AUTOSAR XML (schema 4-2-1)
standard types defined: boolean, float32, uint8, boolean_CompuMethod, boolean_DataConstr, float32_DataConstr, uint8_DataConstr
package /ComponentTypes
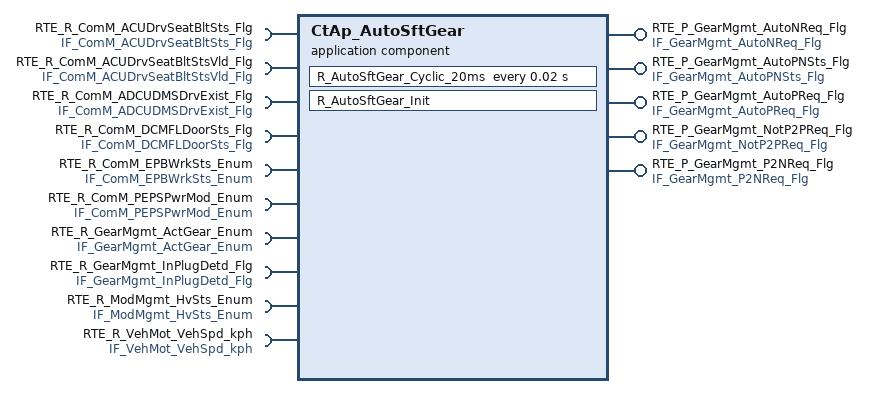
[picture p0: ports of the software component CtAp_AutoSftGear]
  application sw component type CtAp_AutoSftGear
    5 x provide port:
      RTE_P_GearMgmt_AutoNReq_Flg: nonqueued-sender-com-spec{data-element=tec_GearMgmt_AutoNReq_Flg, init-value=0}, provided-interface=IF_GearMgmt_AutoNReq_Flg
      RTE_P_GearMgmt_AutoPNSts_Flg: nonqueued-sender-com-spec{data-element=tec_GearMgmt_AutoPNSts_Flg, init-value=0}, provided-interface=IF_GearMgmt_AutoPNSts_Flg
      RTE_P_GearMgmt_AutoPReq_Flg: nonqueued-sender-com-spec{data-element=tec_GearMgmt_AutoPReq_Flg, init-value=0}, provided-interface=IF_GearMgmt_AutoPReq_Flg
      RTE_P_GearMgmt_NotP2PReq_Flg: nonqueued-sender-com-spec{data-element=tec_GearMgmt_NotP2PReq_Flg, init-value=0}, provided-interface=IF_GearMgmt_NotP2PReq_Flg
      RTE_P_GearMgmt_P2NReq_Flg: nonqueued-sender-com-spec{data-element=tec_GearMgmt_P2NReq_Flg, init-value=0}, provided-interface=IF_GearMgmt_P2NReq_Flg
    10 x require port:
      RTE_R_ComM_ACUDrvSeatBltSts_Flg: nonqueued-receiver-com-spec{data-element=tec_ComM_ACUDrvSeatBltSts_Flg, filter=data-filter-type=ALWAYS, init-value=0}, required-interface=IF_ComM_ACUDrvSeatBltSts_Flg
      RTE_R_ComM_ACUDrvSeatBltStsVld_Flg: nonqueued-receiver-com-spec{data-element=tec_ComM_ACUDrvSeatBltStsVld_Flg, filter=data-filter-type=ALWAYS, init-value=0}, required-interface=IF_ComM_ACUDrvSeatBltStsVld_Flg
      RTE_R_ComM_ADCUDMSDrvExist_Flg: nonqueued-receiver-com-spec{data-element=tec_ComM_ADCUDMSDrvrExist_Flg, filter=data-filter-type=ALWAYS, init-value=0}, required-interface=IF_ComM_ADCUDMSDrvExist_Flg
      RTE_R_ComM_DCMFLDoorSts_Flg: nonqueued-receiver-com-spec{data-element=tec_ComM_DCMFLDoorSts_Flg, filter=data-filter-type=ALWAYS, init-value=0}, required-interface=IF_ComM_DCMFLDoorSts_Flg
      RTE_R_ComM_EPBWrkSts_Enum: nonqueued-receiver-com-spec{data-element=tec_ComM_EPBWrkSts_Enum, filter=data-filter-type=ALWAYS, init-value=0}, required-interface=IF_ComM_EPBWrkSts_Enum
      RTE_R_ComM_PEPSPwrMod_Enum: nonqueued-receiver-com-spec{data-element=tec_ComM_PEPSPwrMod_Enum, filter=data-filter-type=ALWAYS, init-value=0}, required-interface=IF_ComM_PEPSPwrMod_Enum
      RTE_R_GearMgmt_ActGear_Enum: nonqueued-receiver-com-spec{data-element=tec_GearMgmt_ActGear_Enum, filter=data-filter-type=ALWAYS, init-value=0}, required-interface=IF_GearMgmt_ActGear_Enum
      RTE_R_GearMgmt_InPlugDetd_Flg: nonqueued-receiver-com-spec{data-element=tec_GearMgmt_InPlugDetd_Flg, filter=data-filter-type=ALWAYS, init-value=0}, required-interface=IF_GearMgmt_InPlugDetd_Flg
      RTE_R_ModMgmt_HvSts_Enum: nonqueued-receiver-com-spec{data-element=tec_ModMgmt_HvSts_Enum, filter=data-filter-type=ALWAYS, init-value=0}, required-interface=IF_ModMgmt_HvSts_Enum
      RTE_R_VehMot_VehSpd_kph: nonqueued-receiver-com-spec{data-element=tec_VehMot_VehSpd_kph, filter=data-filter-type=ALWAYS, init-value=0}, required-interface=IF_VehMot_VehSpd_kph
    behavior CtAp_AutoSftGear_InternalBehavior
      timing event TMT_R_AutoSftGear_Cyclic_20ms: start-on-event=R_AutoSftGear_Cyclic_20ms, period=0.02
      init event CtAp_AutoSftGear_InitEvent: start-on-event=R_AutoSftGear_Init
      runnable R_AutoSftGear_Cyclic_20ms
        data-receive-point-by-arguments:
          10 x access:
            REC_RTE_R_ComM_ACUDrvSeatBltSts_Flg_tec_ComM_ACUDrvSeatBltSts_Flg: accessed-variable=RTE_R_ComM_ACUDrvSeatBltSts_Flg.tec_ComM_ACUDrvSeatBltSts_Flg
            REC_RTE_R_ComM_ACUDrvSeatBltStsVld_Flg_tec_ComM_ACUDrvSeatBltStsVld_Flg: accessed-variable=RTE_R_ComM_ACUDrvSeatBltStsVld_Flg.tec_ComM_ACUDrvSeatBltStsVld_Flg
            REC_RTE_R_ComM_ADCUDMSDrvExist_Flg_tec_ComM_ADCUDMSDrvrExist_Flg: accessed-variable=RTE_R_ComM_ADCUDMSDrvExist_Flg.tec_ComM_ADCUDMSDrvrExist_Flg
            REC_RTE_R_ComM_DCMFLDoorSts_Flg_tec_ComM_DCMFLDoorSts_Flg: accessed-variable=RTE_R_ComM_DCMFLDoorSts_Flg.tec_ComM_DCMFLDoorSts_Flg
            REC_RTE_R_ComM_EPBWrkSts_Enum_tec_ComM_EPBWrkSts_Enum: accessed-variable=RTE_R_ComM_EPBWrkSts_Enum.tec_ComM_EPBWrkSts_Enum
            REC_RTE_R_ComM_PEPSPwrMod_Enum_tec_ComM_PEPSPwrMod_Enum: accessed-variable=RTE_R_ComM_PEPSPwrMod_Enum.tec_ComM_PEPSPwrMod_Enum
            REC_RTE_R_GearMgmt_ActGear_Enum_tec_GearMgmt_ActGear_Enum: accessed-variable=RTE_R_GearMgmt_ActGear_Enum.tec_GearMgmt_ActGear_Enum
            REC_RTE_R_GearMgmt_InPlugDetd_Flg_tec_GearMgmt_InPlugDetd_Flg: accessed-variable=RTE_R_GearMgmt_InPlugDetd_Flg.tec_GearMgmt_InPlugDetd_Flg
            REC_RTE_R_ModMgmt_HvSts_Enum_tec_ModMgmt_HvSts_Enum: accessed-variable=RTE_R_ModMgmt_HvSts_Enum.tec_ModMgmt_HvSts_Enum
            REC_RTE_R_VehMot_VehSpd_kph_tec_VehMot_VehSpd_kph: accessed-variable=RTE_R_VehMot_VehSpd_kph.tec_VehMot_VehSpd_kph
        data-send-points:
          5 x access:
            SEND_RTE_P_GearMgmt_AutoNReq_Flg_tec_GearMgmt_AutoNReq_Flg: accessed-variable=RTE_P_GearMgmt_AutoNReq_Flg.tec_GearMgmt_AutoNReq_Flg
            SEND_RTE_P_GearMgmt_AutoPNSts_Flg_tec_GearMgmt_AutoPNSts_Flg: accessed-variable=RTE_P_GearMgmt_AutoPNSts_Flg.tec_GearMgmt_AutoPNSts_Flg
            SEND_RTE_P_GearMgmt_AutoPReq_Flg_tec_GearMgmt_AutoPReq_Flg: accessed-variable=RTE_P_GearMgmt_AutoPReq_Flg.tec_GearMgmt_AutoPReq_Flg
            SEND_RTE_P_GearMgmt_NotP2PReq_Flg_tec_GearMgmt_NotP2PReq_Flg: accessed-variable=RTE_P_GearMgmt_NotP2PReq_Flg.tec_GearMgmt_NotP2PReq_Flg
            SEND_RTE_P_GearMgmt_P2NReq_Flg_tec_GearMgmt_P2NReq_Flg: accessed-variable=RTE_P_GearMgmt_P2NReq_Flg.tec_GearMgmt_P2NReq_Flg
      runnable R_AutoSftGear_Init
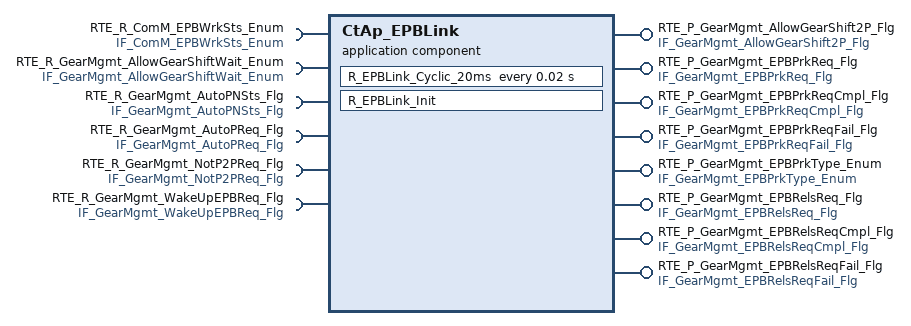
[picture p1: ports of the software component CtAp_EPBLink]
  application sw component type CtAp_EPBLink
    8 x provide port:
      RTE_P_GearMgmt_AllowGearShift2P_Flg: nonqueued-sender-com-spec{data-element=tec_GearMgmt_AllowGearShift2P_Flg, init-value=0}, provided-interface=IF_GearMgmt_AllowGearShift2P_Flg
      RTE_P_GearMgmt_EPBPrkReq_Flg: nonqueued-sender-com-spec{data-element=tec_GearMgmt_EPBPrkReq_Flg, init-value=0}, provided-interface=IF_GearMgmt_EPBPrkReq_Flg
      RTE_P_GearMgmt_EPBPrkReqCmpl_Flg: nonqueued-sender-com-spec{data-element=tec_GearMgmt_EPBPrkReqCmpl_Flg, init-value=0}, provided-interface=IF_GearMgmt_EPBPrkReqCmpl_Flg
      RTE_P_GearMgmt_EPBPrkReqFail_Flg: nonqueued-sender-com-spec{data-element=tec_GearMgmt_EPBPrkReqFail_Flg, init-value=0}, provided-interface=IF_GearMgmt_EPBPrkReqFail_Flg
      RTE_P_GearMgmt_EPBPrkType_Enum: nonqueued-sender-com-spec{data-element=tec_GearMgmt_EPBPrkType_Enum, init-value=0}, provided-interface=IF_GearMgmt_EPBPrkType_Enum
      RTE_P_GearMgmt_EPBRelsReq_Flg: nonqueued-sender-com-spec{data-element=tec_GearMgmt_EPBRelsReq_Flg, init-value=0}, provided-interface=IF_GearMgmt_EPBRelsReq_Flg
      RTE_P_GearMgmt_EPBRelsReqCmpl_Flg: nonqueued-sender-com-spec{data-element=tec_GearMgmt_EPBRelsReqCmpl_Flg, init-value=0}, provided-interface=IF_GearMgmt_EPBRelsReqCmpl_Flg
      RTE_P_GearMgmt_EPBRelsReqFail_Flg: nonqueued-sender-com-spec{data-element=tec_GearMgmt_EPBRelsReqFail_Flg, init-value=0}, provided-interface=IF_GearMgmt_EPBRelsReqFail_Flg
    6 x require port:
      RTE_R_ComM_EPBWrkSts_Enum: nonqueued-receiver-com-spec{data-element=tec_ComM_EPBWrkSts_Enum, filter=data-filter-type=ALWAYS, init-value=0}, required-interface=IF_ComM_EPBWrkSts_Enum
      RTE_R_GearMgmt_AllowGearShiftWait_Enum: nonqueued-receiver-com-spec{data-element=tec_GearMgmt_AllowGearShiftWait_Enum, filter=data-filter-type=ALWAYS, init-value=0}, required-interface=IF_GearMgmt_AllowGearShiftWait_Enum
      RTE_R_GearMgmt_AutoPNSts_Flg: nonqueued-receiver-com-spec{data-element=tec_GearMgmt_AutoPNSts_Flg, filter=data-filter-type=ALWAYS, init-value=0}, required-interface=IF_GearMgmt_AutoPNSts_Flg
      RTE_R_GearMgmt_AutoPReq_Flg: nonqueued-receiver-com-spec{data-element=tec_GearMgmt_AutoPReq_Flg, filter=data-filter-type=ALWAYS, init-value=0}, required-interface=IF_GearMgmt_AutoPReq_Flg
      RTE_R_GearMgmt_NotP2PReq_Flg: nonqueued-receiver-com-spec{data-element=tec_GearMgmt_NotP2PReq_Flg, filter=data-filter-type=ALWAYS, init-value=0}, required-interface=IF_GearMgmt_NotP2PReq_Flg
      RTE_R_GearMgmt_WakeUpEPBReq_Flg: nonqueued-receiver-com-spec{data-element=tec_GearMgmt_WakeUpEPBReq_Flg, filter=data-filter-type=ALWAYS, init-value=0}, required-interface=IF_GearMgmt_WakeUpEPBReq_Flg
    behavior CtAp_EPBLink_InternalBehavior
      timing event TMT_R_EPBLink_Cyclic_20ms: start-on-event=R_EPBLink_Cyclic_20ms, period=0.02
      init event CtAp_EPBLink_InitEvent: start-on-event=R_EPBLink_Init
      runnable R_EPBLink_Cyclic_20ms
        data-receive-point-by-arguments:
          6 x access:
            REC_RTE_R_ComM_EPBWrkSts_Enum_tec_ComM_EPBWrkSts_Enum: accessed-variable=RTE_R_ComM_EPBWrkSts_Enum.tec_ComM_EPBWrkSts_Enum
            REC_RTE_R_GearMgmt_AllowGearShiftWait_Enum_tec_GearMgmt_AllowGearShiftWait_Enum: accessed-variable=RTE_R_GearMgmt_AllowGearShiftWait_Enum.tec_GearMgmt_AllowGearShiftWait_Enum
            REC_RTE_R_GearMgmt_AutoPNSts_Flg_tec_GearMgmt_AutoPNSts_Flg: accessed-variable=RTE_R_GearMgmt_AutoPNSts_Flg.tec_GearMgmt_AutoPNSts_Flg
            REC_RTE_R_GearMgmt_AutoPReq_Flg_tec_GearMgmt_AutoPReq_Flg: accessed-variable=RTE_R_GearMgmt_AutoPReq_Flg.tec_GearMgmt_AutoPReq_Flg
            REC_RTE_R_GearMgmt_NotP2PReq_Flg_tec_GearMgmt_NotP2PReq_Flg: accessed-variable=RTE_R_GearMgmt_NotP2PReq_Flg.tec_GearMgmt_NotP2PReq_Flg
            REC_RTE_R_GearMgmt_WakeUpEPBReq_Flg_tec_GearMgmt_WakeUpEPBReq_Flg: accessed-variable=RTE_R_GearMgmt_WakeUpEPBReq_Flg.tec_GearMgmt_WakeUpEPBReq_Flg
        data-send-points:
          8 x access:
            SEND_RTE_P_GearMgmt_AllowGearShift2P_Flg_tec_GearMgmt_AllowGearShift2P_Flg: accessed-variable=RTE_P_GearMgmt_AllowGearShift2P_Flg.tec_GearMgmt_AllowGearShift2P_Flg
            SEND_RTE_P_GearMgmt_EPBPrkReq_Flg_tec_GearMgmt_EPBPrkReq_Flg: accessed-variable=RTE_P_GearMgmt_EPBPrkReq_Flg.tec_GearMgmt_EPBPrkReq_Flg
            SEND_RTE_P_GearMgmt_EPBPrkReqCmpl_Flg_tec_GearMgmt_EPBPrkReqCmpl_Flg: accessed-variable=RTE_P_GearMgmt_EPBPrkReqCmpl_Flg.tec_GearMgmt_EPBPrkReqCmpl_Flg
            SEND_RTE_P_GearMgmt_EPBPrkReqFail_Flg_tec_GearMgmt_EPBPrkReqFail_Flg: accessed-variable=RTE_P_GearMgmt_EPBPrkReqFail_Flg.tec_GearMgmt_EPBPrkReqFail_Flg
            SEND_RTE_P_GearMgmt_EPBPrkType_Enum_tec_GearMgmt_EPBPrkType_Enum: accessed-variable=RTE_P_GearMgmt_EPBPrkType_Enum.tec_GearMgmt_EPBPrkType_Enum
            SEND_RTE_P_GearMgmt_EPBRelsReq_Flg_tec_GearMgmt_EPBRelsReq_Flg: accessed-variable=RTE_P_GearMgmt_EPBRelsReq_Flg.tec_GearMgmt_EPBRelsReq_Flg
            SEND_RTE_P_GearMgmt_EPBRelsReqCmpl_Flg_tec_GearMgmt_EPBRelsReqCmpl_Flg: accessed-variable=RTE_P_GearMgmt_EPBRelsReqCmpl_Flg.tec_GearMgmt_EPBRelsReqCmpl_Flg
            SEND_RTE_P_GearMgmt_EPBRelsReqFail_Flg_tec_GearMgmt_EPBRelsReqFail_Flg: accessed-variable=RTE_P_GearMgmt_EPBRelsReqFail_Flg.tec_GearMgmt_EPBRelsReqFail_Flg
      runnable R_EPBLink_Init
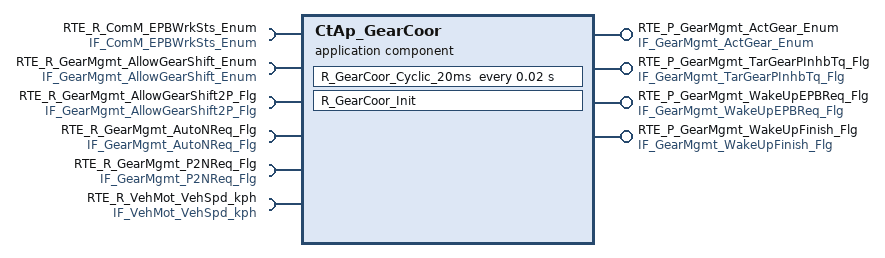
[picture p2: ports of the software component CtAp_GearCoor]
  application sw component type CtAp_GearCoor
    4 x provide port:
      RTE_P_GearMgmt_ActGear_Enum: nonqueued-sender-com-spec{data-element=tec_GearMgmt_ActGear_Enum, init-value=0}, provided-interface=IF_GearMgmt_ActGear_Enum
      RTE_P_GearMgmt_TarGearPInhbTq_Flg: nonqueued-sender-com-spec{data-element=tec_GearMgmt_TarGearPInhbTq_Flg, init-value=0}, provided-interface=IF_GearMgmt_TarGearPInhbTq_Flg
      RTE_P_GearMgmt_WakeUpEPBReq_Flg: nonqueued-sender-com-spec{data-element=tec_GearMgmt_WakeUpEPBReq_Flg, init-value=0}, provided-interface=IF_GearMgmt_WakeUpEPBReq_Flg
      RTE_P_GearMgmt_WakeUpFinish_Flg: nonqueued-sender-com-spec{data-element=tec_GearMgmt_WakeUpFinish_Flg, init-value=0}, provided-interface=IF_GearMgmt_WakeUpFinish_Flg
    6 x require port:
      RTE_R_ComM_EPBWrkSts_Enum: nonqueued-receiver-com-spec{data-element=tec_ComM_EPBWrkSts_Enum, filter=data-filter-type=ALWAYS, init-value=0}, required-interface=IF_ComM_EPBWrkSts_Enum
      RTE_R_GearMgmt_AllowGearShift_Enum: nonqueued-receiver-com-spec{data-element=tec_GearMgmt_AllowGearShift_Enum, filter=data-filter-type=ALWAYS, init-value=0}, required-interface=IF_GearMgmt_AllowGearShift_Enum
      RTE_R_GearMgmt_AllowGearShift2P_Flg: nonqueued-receiver-com-spec{data-element=tec_GearMgmt_AllowGearShift2P_Flg, filter=data-filter-type=ALWAYS, init-value=0}, required-interface=IF_GearMgmt_AllowGearShift2P_Flg
      RTE_R_GearMgmt_AutoNReq_Flg: nonqueued-receiver-com-spec{data-element=tec_GearMgmt_AutoNReq_Flg, filter=data-filter-type=ALWAYS, init-value=0}, required-interface=IF_GearMgmt_AutoNReq_Flg
      RTE_R_GearMgmt_P2NReq_Flg: nonqueued-receiver-com-spec{data-element=tec_GearMgmt_P2NReq_Flg, filter=data-filter-type=ALWAYS, init-value=0}, required-interface=IF_GearMgmt_P2NReq_Flg
      RTE_R_VehMot_VehSpd_kph: nonqueued-receiver-com-spec{data-element=tec_VehMot_VehSpd_kph, filter=data-filter-type=ALWAYS, init-value=0}, required-interface=IF_VehMot_VehSpd_kph
    behavior CtAp_GearCoor_InternalBehavior
      timing event TMT_R_GearCoor_Cyclic_20ms: start-on-event=R_GearCoor_Cyclic_20ms, period=0.02
      init event CtAp_GearCoor_InitEvent: start-on-event=R_GearCoor_Init
      runnable R_GearCoor_Cyclic_20ms
        data-receive-point-by-arguments:
          6 x access:
            REC_RTE_R_ComM_EPBWrkSts_Enum_tec_ComM_EPBWrkSts_Enum: accessed-variable=RTE_R_ComM_EPBWrkSts_Enum.tec_ComM_EPBWrkSts_Enum
            REC_RTE_R_GearMgmt_AllowGearShift_Enum_tec_GearMgmt_AllowGearShift_Enum: accessed-variable=RTE_R_GearMgmt_AllowGearShift_Enum.tec_GearMgmt_AllowGearShift_Enum
            REC_RTE_R_GearMgmt_AllowGearShift2P_Flg_tec_GearMgmt_AllowGearShift2P_Flg: accessed-variable=RTE_R_GearMgmt_AllowGearShift2P_Flg.tec_GearMgmt_AllowGearShift2P_Flg
            REC_RTE_R_GearMgmt_AutoNReq_Flg_tec_GearMgmt_AutoNReq_Flg: accessed-variable=RTE_R_GearMgmt_AutoNReq_Flg.tec_GearMgmt_AutoNReq_Flg
            REC_RTE_R_GearMgmt_P2NReq_Flg_tec_GearMgmt_P2NReq_Flg: accessed-variable=RTE_R_GearMgmt_P2NReq_Flg.tec_GearMgmt_P2NReq_Flg
            REC_RTE_R_VehMot_VehSpd_kph_tec_VehMot_VehSpd_kph: accessed-variable=RTE_R_VehMot_VehSpd_kph.tec_VehMot_VehSpd_kph
        data-send-points:
          4 x access:
            SEND_RTE_P_GearMgmt_ActGear_Enum_tec_GearMgmt_ActGear_Enum: accessed-variable=RTE_P_GearMgmt_ActGear_Enum.tec_GearMgmt_ActGear_Enum
            SEND_RTE_P_GearMgmt_TarGearPInhbTq_Flg_tec_GearMgmt_TarGearPInhbTq_Flg: accessed-variable=RTE_P_GearMgmt_TarGearPInhbTq_Flg.tec_GearMgmt_TarGearPInhbTq_Flg
            SEND_RTE_P_GearMgmt_WakeUpEPBReq_Flg_tec_GearMgmt_WakeUpEPBReq_Flg: accessed-variable=RTE_P_GearMgmt_WakeUpEPBReq_Flg.tec_GearMgmt_WakeUpEPBReq_Flg
            SEND_RTE_P_GearMgmt_WakeUpFinish_Flg_tec_GearMgmt_WakeUpFinish_Flg: accessed-variable=RTE_P_GearMgmt_WakeUpFinish_Flg.tec_GearMgmt_WakeUpFinish_Flg
      runnable R_GearCoor_Init
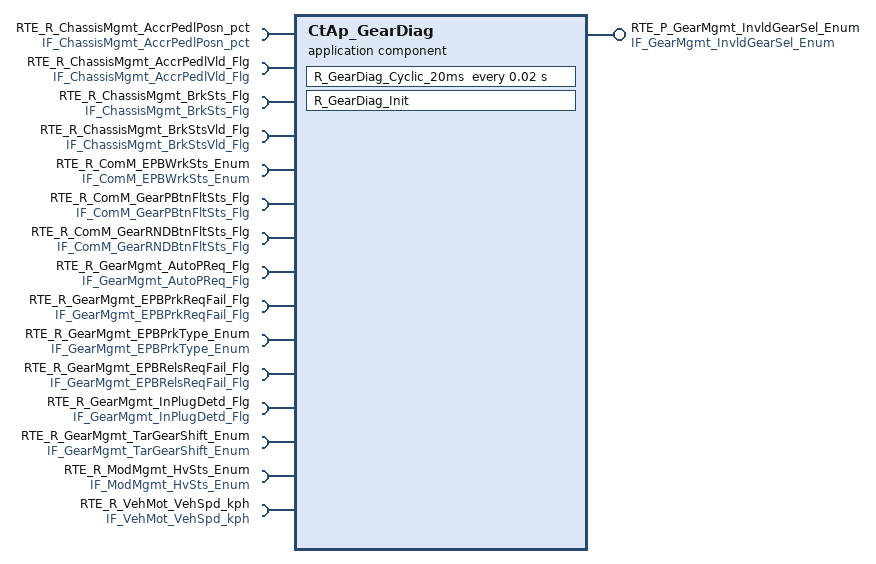
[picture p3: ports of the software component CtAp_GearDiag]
  application sw component type CtAp_GearDiag
    provide port RTE_P_GearMgmt_InvldGearSel_Enum: nonqueued-sender-com-spec{data-element=tec_GearMgmt_InvldGearSel_Enum, init-value=0}, provided-interface=IF_GearMgmt_InvldGearSel_Enum
    15 x require port:
      RTE_R_ChassisMgmt_AccrPedlPosn_pct: nonqueued-receiver-com-spec{data-element=tec_ChassisMgmt_AccrPedlPosn_pct, filter=data-filter-type=ALWAYS, init-value=0}, required-interface=IF_ChassisMgmt_AccrPedlPosn_pct
      RTE_R_ChassisMgmt_AccrPedlVld_Flg: nonqueued-receiver-com-spec{data-element=tec_ChassisMgmt_AccrPedlVld_Flg, filter=data-filter-type=ALWAYS, init-value=0}, required-interface=IF_ChassisMgmt_AccrPedlVld_Flg
      RTE_R_ChassisMgmt_BrkSts_Flg: nonqueued-receiver-com-spec{data-element=tec_ChassisMgmt_BrkSts_Flg, filter=data-filter-type=ALWAYS, init-value=0}, required-interface=IF_ChassisMgmt_BrkSts_Flg
      RTE_R_ChassisMgmt_BrkStsVld_Flg: nonqueued-receiver-com-spec{data-element=tec_ChassisMgmt_BrkStsVld_Flg, filter=data-filter-type=ALWAYS, init-value=0}, required-interface=IF_ChassisMgmt_BrkStsVld_Flg
      RTE_R_ComM_EPBWrkSts_Enum: nonqueued-receiver-com-spec{data-element=tec_ComM_EPBWrkSts_Enum, filter=data-filter-type=ALWAYS, init-value=0}, required-interface=IF_ComM_EPBWrkSts_Enum
      RTE_R_ComM_GearPBtnFltSts_Flg: nonqueued-receiver-com-spec{data-element=tec_ComM_GearPBtnFltSts_Flg, filter=data-filter-type=ALWAYS, init-value=0}, required-interface=IF_ComM_GearPBtnFltSts_Flg
      RTE_R_ComM_GearRNDBtnFltSts_Flg: nonqueued-receiver-com-spec{data-element=tec_ComM_GearRNDBtnFltSts_Flg, filter=data-filter-type=ALWAYS, init-value=0}, required-interface=IF_ComM_GearRNDBtnFltSts_Flg
      RTE_R_GearMgmt_AutoPReq_Flg: nonqueued-receiver-com-spec{data-element=tec_GearMgmt_AutoPReq_Flg, filter=data-filter-type=ALWAYS, init-value=0}, required-interface=IF_GearMgmt_AutoPReq_Flg
      RTE_R_GearMgmt_EPBPrkReqFail_Flg: nonqueued-receiver-com-spec{data-element=tec_GearMgmt_EPBPrkReqFail_Flg, filter=data-filter-type=ALWAYS, init-value=0}, required-interface=IF_GearMgmt_EPBPrkReqFail_Flg
      RTE_R_GearMgmt_EPBPrkType_Enum: nonqueued-receiver-com-spec{data-element=tec_GearMgmt_EPBPrkType_Enum, filter=data-filter-type=ALWAYS, init-value=0}, required-interface=IF_GearMgmt_EPBPrkType_Enum
      RTE_R_GearMgmt_EPBRelsReqFail_Flg: nonqueued-receiver-com-spec{data-element=tec_GearMgmt_EPBRelsReqFail_Flg, filter=data-filter-type=ALWAYS, init-value=0}, required-interface=IF_GearMgmt_EPBRelsReqFail_Flg
      RTE_R_GearMgmt_InPlugDetd_Flg: nonqueued-receiver-com-spec{data-element=tec_GearMgmt_InPlugDetd_Flg, filter=data-filter-type=ALWAYS, init-value=0}, required-interface=IF_GearMgmt_InPlugDetd_Flg
      RTE_R_GearMgmt_TarGearShift_Enum: nonqueued-receiver-com-spec{data-element=tec_GearMgmt_TarGearShift_Enum, filter=data-filter-type=ALWAYS, init-value=0}, required-interface=IF_GearMgmt_TarGearShift_Enum
      RTE_R_ModMgmt_HvSts_Enum: nonqueued-receiver-com-spec{data-element=tec_ModMgmt_HvSts_Enum, filter=data-filter-type=ALWAYS, init-value=0}, required-interface=IF_ModMgmt_HvSts_Enum
      RTE_R_VehMot_VehSpd_kph: nonqueued-receiver-com-spec{data-element=tec_VehMot_VehSpd_kph, filter=data-filter-type=ALWAYS, init-value=0}, required-interface=IF_VehMot_VehSpd_kph
    behavior CtAp_GearDiag_InternalBehavior
      timing event TMT_R_GearDiag_Cyclic_20ms: start-on-event=R_GearDiag_Cyclic_20ms, period=0.02
      init event CtAp_GearDiag_InitEvent: start-on-event=R_GearDiag_Init
      runnable R_GearDiag_Cyclic_20ms
        data-receive-point-by-arguments:
          15 x access:
            REC_RTE_R_ChassisMgmt_AccrPedlPosn_pct_tec_ChassisMgmt_AccrPedlPosn_pct: accessed-variable=RTE_R_ChassisMgmt_AccrPedlPosn_pct.tec_ChassisMgmt_AccrPedlPosn_pct
            REC_RTE_R_ChassisMgmt_AccrPedlVld_Flg_tec_ChassisMgmt_AccrPedlVld_Flg: accessed-variable=RTE_R_ChassisMgmt_AccrPedlVld_Flg.tec_ChassisMgmt_AccrPedlVld_Flg
            REC_RTE_R_ChassisMgmt_BrkSts_Flg_tec_ChassisMgmt_BrkSts_Flg: accessed-variable=RTE_R_ChassisMgmt_BrkSts_Flg.tec_ChassisMgmt_BrkSts_Flg
            REC_RTE_R_ChassisMgmt_BrkStsVld_Flg_tec_ChassisMgmt_BrkStsVld_Flg: accessed-variable=RTE_R_ChassisMgmt_BrkStsVld_Flg.tec_ChassisMgmt_BrkStsVld_Flg
            REC_RTE_R_ComM_EPBWrkSts_Enum_tec_ComM_EPBWrkSts_Enum: accessed-variable=RTE_R_ComM_EPBWrkSts_Enum.tec_ComM_EPBWrkSts_Enum
            REC_RTE_R_ComM_GearPBtnFltSts_Flg_tec_ComM_GearPBtnFltSts_Flg: accessed-variable=RTE_R_ComM_GearPBtnFltSts_Flg.tec_ComM_GearPBtnFltSts_Flg
            REC_RTE_R_ComM_GearRNDBtnFltSts_Flg_tec_ComM_GearRNDBtnFltSts_Flg: accessed-variable=RTE_R_ComM_GearRNDBtnFltSts_Flg.tec_ComM_GearRNDBtnFltSts_Flg
            REC_RTE_R_GearMgmt_AutoPReq_Flg_tec_GearMgmt_AutoPReq_Flg: accessed-variable=RTE_R_GearMgmt_AutoPReq_Flg.tec_GearMgmt_AutoPReq_Flg
            REC_RTE_R_GearMgmt_EPBPrkReqFail_Flg_tec_GearMgmt_EPBPrkReqFail_Flg: accessed-variable=RTE_R_GearMgmt_EPBPrkReqFail_Flg.tec_GearMgmt_EPBPrkReqFail_Flg
            REC_RTE_R_GearMgmt_EPBPrkType_Enum_tec_GearMgmt_EPBPrkType_Enum: accessed-variable=RTE_R_GearMgmt_EPBPrkType_Enum.tec_GearMgmt_EPBPrkType_Enum
            REC_RTE_R_GearMgmt_EPBRelsReqFail_Flg_tec_GearMgmt_EPBRelsReqFail_Flg: accessed-variable=RTE_R_GearMgmt_EPBRelsReqFail_Flg.tec_GearMgmt_EPBRelsReqFail_Flg
            REC_RTE_R_GearMgmt_InPlugDetd_Flg_tec_GearMgmt_InPlugDetd_Flg: accessed-variable=RTE_R_GearMgmt_InPlugDetd_Flg.tec_GearMgmt_InPlugDetd_Flg
            REC_RTE_R_GearMgmt_TarGearShift_Enum_tec_GearMgmt_TarGearShift_Enum: accessed-variable=RTE_R_GearMgmt_TarGearShift_Enum.tec_GearMgmt_TarGearShift_Enum
            REC_RTE_R_ModMgmt_HvSts_Enum_tec_ModMgmt_HvSts_Enum: accessed-variable=RTE_R_ModMgmt_HvSts_Enum.tec_ModMgmt_HvSts_Enum
            REC_RTE_R_VehMot_VehSpd_kph_tec_VehMot_VehSpd_kph: accessed-variable=RTE_R_VehMot_VehSpd_kph.tec_VehMot_VehSpd_kph
        data-send-points:
          access SEND_RTE_P_GearMgmt_InvldGearSel_Enum_tec_GearMgmt_InvldGearSel_Enum: accessed-variable=RTE_P_GearMgmt_InvldGearSel_Enum.tec_GearMgmt_InvldGearSel_Enum
      runnable R_GearDiag_Init
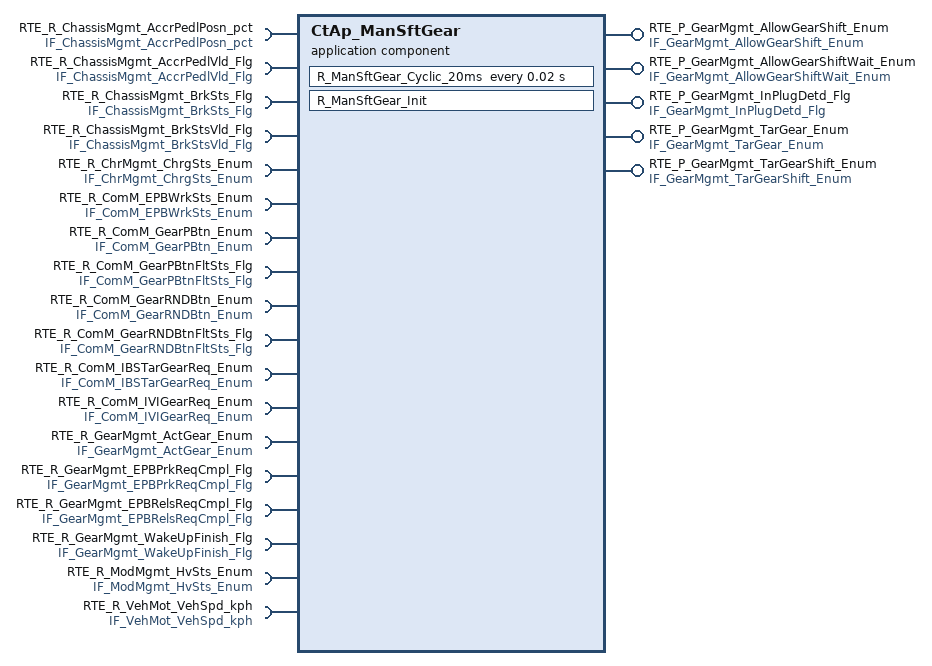
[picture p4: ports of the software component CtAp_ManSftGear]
  application sw component type CtAp_ManSftGear
    5 x provide port:
      RTE_P_GearMgmt_AllowGearShift_Enum: nonqueued-sender-com-spec{data-element=tec_GearMgmt_AllowGearShift_Enum, init-value=0}, provided-interface=IF_GearMgmt_AllowGearShift_Enum
      RTE_P_GearMgmt_AllowGearShiftWait_Enum: nonqueued-sender-com-spec{data-element=tec_GearMgmt_AllowGearShiftWait_Enum, init-value=0}, provided-interface=IF_GearMgmt_AllowGearShiftWait_Enum
      RTE_P_GearMgmt_InPlugDetd_Flg: nonqueued-sender-com-spec{data-element=tec_GearMgmt_InPlugDetd_Flg, init-value=0}, provided-interface=IF_GearMgmt_InPlugDetd_Flg
      RTE_P_GearMgmt_TarGear_Enum: nonqueued-sender-com-spec{data-element=tec_GearMgmt_TarGear_Enum, init-value=0}, provided-interface=IF_GearMgmt_TarGear_Enum
      RTE_P_GearMgmt_TarGearShift_Enum: nonqueued-sender-com-spec{data-element=tec_GearMgmt_TarGearShift_Enum, init-value=0}, provided-interface=IF_GearMgmt_TarGearShift_Enum
    18 x require port:
      RTE_R_ChassisMgmt_AccrPedlPosn_pct: nonqueued-receiver-com-spec{data-element=tec_ChassisMgmt_AccrPedlPosn_pct, filter=data-filter-type=ALWAYS, init-value=0}, required-interface=IF_ChassisMgmt_AccrPedlPosn_pct
      RTE_R_ChassisMgmt_AccrPedlVld_Flg: nonqueued-receiver-com-spec{data-element=tec_ChassisMgmt_AccrPedlVld_Flg, filter=data-filter-type=ALWAYS, init-value=0}, required-interface=IF_ChassisMgmt_AccrPedlVld_Flg
      RTE_R_ChassisMgmt_BrkSts_Flg: nonqueued-receiver-com-spec{data-element=tec_ChassisMgmt_BrkSts_Flg, filter=data-filter-type=ALWAYS, init-value=0}, required-interface=IF_ChassisMgmt_BrkSts_Flg
      RTE_R_ChassisMgmt_BrkStsVld_Flg: nonqueued-receiver-com-spec{data-element=tec_ChassisMgmt_BrkStsVld_Flg, filter=data-filter-type=ALWAYS, init-value=0}, required-interface=IF_ChassisMgmt_BrkStsVld_Flg
      RTE_R_ChrMgmt_ChrgSts_Enum: nonqueued-receiver-com-spec{data-element=tec_ChrMgmt_ChrgSts_Enum, filter=data-filter-type=ALWAYS, init-value=0}, required-interface=IF_ChrMgmt_ChrgSts_Enum
      RTE_R_ComM_EPBWrkSts_Enum: nonqueued-receiver-com-spec{data-element=tec_ComM_EPBWrkSts_Enum, filter=data-filter-type=ALWAYS, init-value=0}, required-interface=IF_ComM_EPBWrkSts_Enum
      RTE_R_ComM_GearPBtn_Enum: nonqueued-receiver-com-spec{data-element=tec_ComM_GearPBtn_Enum, filter=data-filter-type=ALWAYS, init-value=0}, required-interface=IF_ComM_GearPBtn_Enum
      RTE_R_ComM_GearPBtnFltSts_Flg: nonqueued-receiver-com-spec{data-element=tec_ComM_GearPBtnFltSts_Flg, filter=data-filter-type=ALWAYS, init-value=0}, required-interface=IF_ComM_GearPBtnFltSts_Flg
      RTE_R_ComM_GearRNDBtn_Enum: nonqueued-receiver-com-spec{data-element=tec_ComM_GearRNDBtn_Enum, filter=data-filter-type=ALWAYS, init-value=0}, required-interface=IF_ComM_GearRNDBtn_Enum
      RTE_R_ComM_GearRNDBtnFltSts_Flg: nonqueued-receiver-com-spec{data-element=tec_ComM_GearRNDBtnFltSts_Flg, filter=data-filter-type=ALWAYS, init-value=0}, required-interface=IF_ComM_GearRNDBtnFltSts_Flg
      RTE_R_ComM_IBSTarGearReq_Enum: nonqueued-receiver-com-spec{data-element=tec_ComM_IBSTarGearReq_Enum, filter=data-filter-type=ALWAYS, init-value=0}, required-interface=IF_ComM_IBSTarGearReq_Enum
      RTE_R_ComM_IVIGearReq_Enum: nonqueued-receiver-com-spec{data-element=tec_ComM_IVIGearReq_Enum, filter=data-filter-type=ALWAYS, init-value=0}, required-interface=IF_ComM_IVIGearReq_Enum
      RTE_R_GearMgmt_ActGear_Enum: nonqueued-receiver-com-spec{data-element=tec_GearMgmt_ActGear_Enum, filter=data-filter-type=ALWAYS, init-value=0}, required-interface=IF_GearMgmt_ActGear_Enum
      RTE_R_GearMgmt_EPBPrkReqCmpl_Flg: nonqueued-receiver-com-spec{data-element=tec_GearMgmt_EPBPrkReqCmpl_Flg, filter=data-filter-type=ALWAYS, init-value=0}, required-interface=IF_GearMgmt_EPBPrkReqCmpl_Flg
      RTE_R_GearMgmt_EPBRelsReqCmpl_Flg: nonqueued-receiver-com-spec{data-element=tec_GearMgmt_EPBRelsReqCmpl_Flg, filter=data-filter-type=ALWAYS, init-value=0}, required-interface=IF_GearMgmt_EPBRelsReqCmpl_Flg
      RTE_R_GearMgmt_WakeUpFinish_Flg: nonqueued-receiver-com-spec{data-element=tec_GearMgmt_WakeUpFinish_Flg, filter=data-filter-type=ALWAYS, init-value=0}, required-interface=IF_GearMgmt_WakeUpFinish_Flg
      RTE_R_ModMgmt_HvSts_Enum: nonqueued-receiver-com-spec{data-element=tec_ModMgmt_HvSts_Enum, filter=data-filter-type=ALWAYS, init-value=0}, required-interface=IF_ModMgmt_HvSts_Enum
      RTE_R_VehMot_VehSpd_kph: nonqueued-receiver-com-spec{data-element=tec_VehMot_VehSpd_kph, filter=data-filter-type=ALWAYS, init-value=0}, required-interface=IF_VehMot_VehSpd_kph
    behavior CtAp_ManSftGear_InternalBehavior
      timing event TMT_R_ManSftGear_Cyclic_20ms: start-on-event=R_ManSftGear_Cyclic_20ms, period=0.02
      init event CtAp_ManSftGear_InitEvent: start-on-event=R_ManSftGear_Init
      runnable R_ManSftGear_Cyclic_20ms
        data-receive-point-by-arguments:
          18 x access:
            REC_RTE_R_ChassisMgmt_AccrPedlPosn_pct_tec_ChassisMgmt_AccrPedlPosn_pct: accessed-variable=RTE_R_ChassisMgmt_AccrPedlPosn_pct.tec_ChassisMgmt_AccrPedlPosn_pct
            REC_RTE_R_ChassisMgmt_AccrPedlVld_Flg_tec_ChassisMgmt_AccrPedlVld_Flg: accessed-variable=RTE_R_ChassisMgmt_AccrPedlVld_Flg.tec_ChassisMgmt_AccrPedlVld_Flg
            REC_RTE_R_ChassisMgmt_BrkSts_Flg_tec_ChassisMgmt_BrkSts_Flg: accessed-variable=RTE_R_ChassisMgmt_BrkSts_Flg.tec_ChassisMgmt_BrkSts_Flg
            REC_RTE_R_ChassisMgmt_BrkStsVld_Flg_tec_ChassisMgmt_BrkStsVld_Flg: accessed-variable=RTE_R_ChassisMgmt_BrkStsVld_Flg.tec_ChassisMgmt_BrkStsVld_Flg
            REC_RTE_R_ChrMgmt_ChrgSts_Enum_tec_ChrMgmt_ChrgSts_Enum: accessed-variable=RTE_R_ChrMgmt_ChrgSts_Enum.tec_ChrMgmt_ChrgSts_Enum
            REC_RTE_R_ComM_EPBWrkSts_Enum_tec_ComM_EPBWrkSts_Enum: accessed-variable=RTE_R_ComM_EPBWrkSts_Enum.tec_ComM_EPBWrkSts_Enum
            REC_RTE_R_ComM_GearPBtn_Enum_tec_ComM_GearPBtn_Enum: accessed-variable=RTE_R_ComM_GearPBtn_Enum.tec_ComM_GearPBtn_Enum
            REC_RTE_R_ComM_GearPBtnFltSts_Flg_tec_ComM_GearPBtnFltSts_Flg: accessed-variable=RTE_R_ComM_GearPBtnFltSts_Flg.tec_ComM_GearPBtnFltSts_Flg
            REC_RTE_R_ComM_GearRNDBtn_Enum_tec_ComM_GearRNDBtn_Enum: accessed-variable=RTE_R_ComM_GearRNDBtn_Enum.tec_ComM_GearRNDBtn_Enum
            REC_RTE_R_ComM_GearRNDBtnFltSts_Flg_tec_ComM_GearRNDBtnFltSts_Flg: accessed-variable=RTE_R_ComM_GearRNDBtnFltSts_Flg.tec_ComM_GearRNDBtnFltSts_Flg
            REC_RTE_R_ComM_IBSTarGearReq_Enum_tec_ComM_IBSTarGearReq_Enum: accessed-variable=RTE_R_ComM_IBSTarGearReq_Enum.tec_ComM_IBSTarGearReq_Enum
            REC_RTE_R_ComM_IVIGearReq_Enum_tec_ComM_IVIGearReq_Enum: accessed-variable=RTE_R_ComM_IVIGearReq_Enum.tec_ComM_IVIGearReq_Enum
            REC_RTE_R_GearMgmt_ActGear_Enum_tec_GearMgmt_ActGear_Enum: accessed-variable=RTE_R_GearMgmt_ActGear_Enum.tec_GearMgmt_ActGear_Enum
            REC_RTE_R_GearMgmt_EPBPrkReqCmpl_Flg_tec_GearMgmt_EPBPrkReqCmpl_Flg: accessed-variable=RTE_R_GearMgmt_EPBPrkReqCmpl_Flg.tec_GearMgmt_EPBPrkReqCmpl_Flg
            REC_RTE_R_GearMgmt_EPBRelsReqCmpl_Flg_tec_GearMgmt_EPBRelsReqCmpl_Flg: accessed-variable=RTE_R_GearMgmt_EPBRelsReqCmpl_Flg.tec_GearMgmt_EPBRelsReqCmpl_Flg
            REC_RTE_R_GearMgmt_WakeUpFinish_Flg_tec_GearMgmt_WakeUpFinish_Flg: accessed-variable=RTE_R_GearMgmt_WakeUpFinish_Flg.tec_GearMgmt_WakeUpFinish_Flg
            REC_RTE_R_ModMgmt_HvSts_Enum_tec_ModMgmt_HvSts_Enum: accessed-variable=RTE_R_ModMgmt_HvSts_Enum.tec_ModMgmt_HvSts_Enum
            REC_RTE_R_VehMot_VehSpd_kph_tec_VehMot_VehSpd_kph: accessed-variable=RTE_R_VehMot_VehSpd_kph.tec_VehMot_VehSpd_kph
        data-send-points:
          5 x access:
            SEND_RTE_P_GearMgmt_AllowGearShift_Enum_tec_GearMgmt_AllowGearShift_Enum: accessed-variable=RTE_P_GearMgmt_AllowGearShift_Enum.tec_GearMgmt_AllowGearShift_Enum
            SEND_RTE_P_GearMgmt_AllowGearShiftWait_Enum_tec_GearMgmt_AllowGearShiftWait_Enum: accessed-variable=RTE_P_GearMgmt_AllowGearShiftWait_Enum.tec_GearMgmt_AllowGearShiftWait_Enum
            SEND_RTE_P_GearMgmt_InPlugDetd_Flg_tec_GearMgmt_InPlugDetd_Flg: accessed-variable=RTE_P_GearMgmt_InPlugDetd_Flg.tec_GearMgmt_InPlugDetd_Flg
            SEND_RTE_P_GearMgmt_TarGear_Enum_tec_GearMgmt_TarGear_Enum: accessed-variable=RTE_P_GearMgmt_TarGear_Enum.tec_GearMgmt_TarGear_Enum
            SEND_RTE_P_GearMgmt_TarGearShift_Enum_tec_GearMgmt_TarGearShift_Enum: accessed-variable=RTE_P_GearMgmt_TarGearShift_Enum.tec_GearMgmt_TarGearShift_Enum
      runnable R_ManSftGear_Init
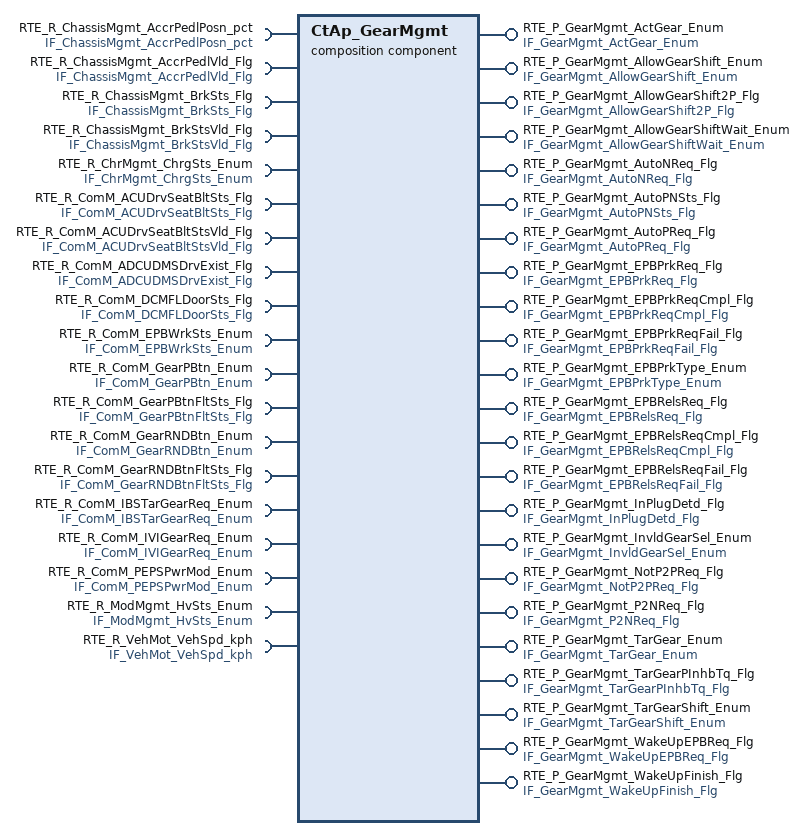
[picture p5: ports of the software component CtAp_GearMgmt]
  composition sw component type CtAp_GearMgmt
    23 x provide port:
      RTE_P_GearMgmt_ActGear_Enum: nonqueued-sender-com-spec{data-element=tec_GearMgmt_ActGear_Enum, init-value=0}, provided-interface=IF_GearMgmt_ActGear_Enum
      RTE_P_GearMgmt_AllowGearShift_Enum: nonqueued-sender-com-spec{data-element=tec_GearMgmt_AllowGearShift_Enum, init-value=0}, provided-interface=IF_GearMgmt_AllowGearShift_Enum
      RTE_P_GearMgmt_AllowGearShift2P_Flg: nonqueued-sender-com-spec{data-element=tec_GearMgmt_AllowGearShift2P_Flg, init-value=0}, provided-interface=IF_GearMgmt_AllowGearShift2P_Flg
      RTE_P_GearMgmt_AllowGearShiftWait_Enum: nonqueued-sender-com-spec{data-element=tec_GearMgmt_AllowGearShiftWait_Enum, init-value=0}, provided-interface=IF_GearMgmt_AllowGearShiftWait_Enum
      RTE_P_GearMgmt_AutoNReq_Flg: nonqueued-sender-com-spec{data-element=tec_GearMgmt_AutoNReq_Flg, init-value=0}, provided-interface=IF_GearMgmt_AutoNReq_Flg
      RTE_P_GearMgmt_AutoPNSts_Flg: nonqueued-sender-com-spec{data-element=tec_GearMgmt_AutoPNSts_Flg, init-value=0}, provided-interface=IF_GearMgmt_AutoPNSts_Flg
      RTE_P_GearMgmt_AutoPReq_Flg: nonqueued-sender-com-spec{data-element=tec_GearMgmt_AutoPReq_Flg, init-value=0}, provided-interface=IF_GearMgmt_AutoPReq_Flg
      RTE_P_GearMgmt_EPBPrkReq_Flg: nonqueued-sender-com-spec{data-element=tec_GearMgmt_EPBPrkReq_Flg, init-value=0}, provided-interface=IF_GearMgmt_EPBPrkReq_Flg
      RTE_P_GearMgmt_EPBPrkReqCmpl_Flg: nonqueued-sender-com-spec{data-element=tec_GearMgmt_EPBPrkReqCmpl_Flg, init-value=0}, provided-interface=IF_GearMgmt_EPBPrkReqCmpl_Flg
      RTE_P_GearMgmt_EPBPrkReqFail_Flg: nonqueued-sender-com-spec{data-element=tec_GearMgmt_EPBPrkReqFail_Flg, init-value=0}, provided-interface=IF_GearMgmt_EPBPrkReqFail_Flg
      RTE_P_GearMgmt_EPBPrkType_Enum: nonqueued-sender-com-spec{data-element=tec_GearMgmt_EPBPrkType_Enum, init-value=0}, provided-interface=IF_GearMgmt_EPBPrkType_Enum
      RTE_P_GearMgmt_EPBRelsReq_Flg: nonqueued-sender-com-spec{data-element=tec_GearMgmt_EPBRelsReq_Flg, init-value=0}, provided-interface=IF_GearMgmt_EPBRelsReq_Flg
      RTE_P_GearMgmt_EPBRelsReqCmpl_Flg: nonqueued-sender-com-spec{data-element=tec_GearMgmt_EPBRelsReqCmpl_Flg, init-value=0}, provided-interface=IF_GearMgmt_EPBRelsReqCmpl_Flg
      RTE_P_GearMgmt_EPBRelsReqFail_Flg: nonqueued-sender-com-spec{data-element=tec_GearMgmt_EPBRelsReqFail_Flg, init-value=0}, provided-interface=IF_GearMgmt_EPBRelsReqFail_Flg
      RTE_P_GearMgmt_InPlugDetd_Flg: nonqueued-sender-com-spec{data-element=tec_GearMgmt_InPlugDetd_Flg, init-value=0}, provided-interface=IF_GearMgmt_InPlugDetd_Flg
      RTE_P_GearMgmt_InvldGearSel_Enum: nonqueued-sender-com-spec{data-element=tec_GearMgmt_InvldGearSel_Enum, init-value=0}, provided-interface=IF_GearMgmt_InvldGearSel_Enum
      RTE_P_GearMgmt_NotP2PReq_Flg: nonqueued-sender-com-spec{data-element=tec_GearMgmt_NotP2PReq_Flg, init-value=0}, provided-interface=IF_GearMgmt_NotP2PReq_Flg
      RTE_P_GearMgmt_P2NReq_Flg: nonqueued-sender-com-spec{data-element=tec_GearMgmt_P2NReq_Flg, init-value=0}, provided-interface=IF_GearMgmt_P2NReq_Flg
      RTE_P_GearMgmt_TarGear_Enum: nonqueued-sender-com-spec{data-element=tec_GearMgmt_TarGear_Enum, init-value=0}, provided-interface=IF_GearMgmt_TarGear_Enum
      RTE_P_GearMgmt_TarGearPInhbTq_Flg: nonqueued-sender-com-spec{data-element=tec_GearMgmt_TarGearPInhbTq_Flg, init-value=0}, provided-interface=IF_GearMgmt_TarGearPInhbTq_Flg
      RTE_P_GearMgmt_TarGearShift_Enum: nonqueued-sender-com-spec{data-element=tec_GearMgmt_TarGearShift_Enum, init-value=0}, provided-interface=IF_GearMgmt_TarGearShift_Enum
      RTE_P_GearMgmt_WakeUpEPBReq_Flg: nonqueued-sender-com-spec{data-element=tec_GearMgmt_WakeUpEPBReq_Flg, init-value=0}, provided-interface=IF_GearMgmt_WakeUpEPBReq_Flg
      RTE_P_GearMgmt_WakeUpFinish_Flg: nonqueued-sender-com-spec{data-element=tec_GearMgmt_WakeUpFinish_Flg, init-value=0}, provided-interface=IF_GearMgmt_WakeUpFinish_Flg
    19 x require port:
      RTE_R_ChassisMgmt_AccrPedlPosn_pct: nonqueued-receiver-com-spec{data-element=tec_ChassisMgmt_AccrPedlPosn_pct, filter=data-filter-type=ALWAYS, init-value=0}, required-interface=IF_ChassisMgmt_AccrPedlPosn_pct
      RTE_R_ChassisMgmt_AccrPedlVld_Flg: nonqueued-receiver-com-spec{data-element=tec_ChassisMgmt_AccrPedlVld_Flg, filter=data-filter-type=ALWAYS, init-value=0}, required-interface=IF_ChassisMgmt_AccrPedlVld_Flg
      RTE_R_ChassisMgmt_BrkSts_Flg: nonqueued-receiver-com-spec{data-element=tec_ChassisMgmt_BrkSts_Flg, filter=data-filter-type=ALWAYS, init-value=0}, required-interface=IF_ChassisMgmt_BrkSts_Flg
      RTE_R_ChassisMgmt_BrkStsVld_Flg: nonqueued-receiver-com-spec{data-element=tec_ChassisMgmt_BrkStsVld_Flg, filter=data-filter-type=ALWAYS, init-value=0}, required-interface=IF_ChassisMgmt_BrkStsVld_Flg
      RTE_R_ChrMgmt_ChrgSts_Enum: nonqueued-receiver-com-spec{data-element=tec_ChrMgmt_ChrgSts_Enum, filter=data-filter-type=ALWAYS, init-value=0}, required-interface=IF_ChrMgmt_ChrgSts_Enum
      RTE_R_ComM_ACUDrvSeatBltSts_Flg: nonqueued-receiver-com-spec{data-element=tec_ComM_ACUDrvSeatBltSts_Flg, filter=data-filter-type=ALWAYS, init-value=0}, required-interface=IF_ComM_ACUDrvSeatBltSts_Flg
      RTE_R_ComM_ACUDrvSeatBltStsVld_Flg: nonqueued-receiver-com-spec{data-element=tec_ComM_ACUDrvSeatBltStsVld_Flg, filter=data-filter-type=ALWAYS, init-value=0}, required-interface=IF_ComM_ACUDrvSeatBltStsVld_Flg
      RTE_R_ComM_ADCUDMSDrvExist_Flg: nonqueued-receiver-com-spec{data-element=tec_ComM_ADCUDMSDrvrExist_Flg, filter=data-filter-type=ALWAYS, init-value=0}, required-interface=IF_ComM_ADCUDMSDrvExist_Flg
      RTE_R_ComM_DCMFLDoorSts_Flg: nonqueued-receiver-com-spec{data-element=tec_ComM_DCMFLDoorSts_Flg, filter=data-filter-type=ALWAYS, init-value=0}, required-interface=IF_ComM_DCMFLDoorSts_Flg
      RTE_R_ComM_EPBWrkSts_Enum: nonqueued-receiver-com-spec{data-element=tec_ComM_EPBWrkSts_Enum, filter=data-filter-type=ALWAYS, init-value=0}, required-interface=IF_ComM_EPBWrkSts_Enum
      RTE_R_ComM_GearPBtn_Enum: nonqueued-receiver-com-spec{data-element=tec_ComM_GearPBtn_Enum, filter=data-filter-type=ALWAYS, init-value=0}, required-interface=IF_ComM_GearPBtn_Enum
      RTE_R_ComM_GearPBtnFltSts_Flg: nonqueued-receiver-com-spec{data-element=tec_ComM_GearPBtnFltSts_Flg, filter=data-filter-type=ALWAYS, init-value=0}, required-interface=IF_ComM_GearPBtnFltSts_Flg
      RTE_R_ComM_GearRNDBtn_Enum: nonqueued-receiver-com-spec{data-element=tec_ComM_GearRNDBtn_Enum, filter=data-filter-type=ALWAYS, init-value=0}, required-interface=IF_ComM_GearRNDBtn_Enum
      RTE_R_ComM_GearRNDBtnFltSts_Flg: nonqueued-receiver-com-spec{data-element=tec_ComM_GearRNDBtnFltSts_Flg, filter=data-filter-type=ALWAYS, init-value=0}, required-interface=IF_ComM_GearRNDBtnFltSts_Flg
      RTE_R_ComM_IBSTarGearReq_Enum: nonqueued-receiver-com-spec{data-element=tec_ComM_IBSTarGearReq_Enum, filter=data-filter-type=ALWAYS, init-value=0}, required-interface=IF_ComM_IBSTarGearReq_Enum
      RTE_R_ComM_IVIGearReq_Enum: nonqueued-receiver-com-spec{data-element=tec_ComM_IVIGearReq_Enum, filter=data-filter-type=ALWAYS, init-value=0}, required-interface=IF_ComM_IVIGearReq_Enum
      RTE_R_ComM_PEPSPwrMod_Enum: nonqueued-receiver-com-spec{data-element=tec_ComM_PEPSPwrMod_Enum, filter=data-filter-type=ALWAYS, init-value=0}, required-interface=IF_ComM_PEPSPwrMod_Enum
      RTE_R_ModMgmt_HvSts_Enum: nonqueued-receiver-com-spec{data-element=tec_ModMgmt_HvSts_Enum, filter=data-filter-type=ALWAYS, init-value=0}, required-interface=IF_ModMgmt_HvSts_Enum
      RTE_R_VehMot_VehSpd_kph: nonqueued-receiver-com-spec{data-element=tec_VehMot_VehSpd_kph, filter=data-filter-type=ALWAYS, init-value=0}, required-interface=IF_VehMot_VehSpd_kph
    5 x component:
      CtAp_AutoSftGear: type=CtAp_AutoSftGear
      CtAp_EPBLink: type=CtAp_EPBLink
      CtAp_GearCoor: type=CtAp_GearCoor
      CtAp_GearDiag: type=CtAp_GearDiag
      CtAp_ManSftGear: type=CtAp_ManSftGear
    connect CtAp_AutoSftGear.RTE_P_GearMgmt_AutoPNSts_Flg -> CtAp_EPBLink.RTE_R_GearMgmt_AutoPNSts_Flg
    connect CtAp_AutoSftGear.RTE_P_GearMgmt_AutoPReq_Flg -> CtAp_EPBLink.RTE_R_GearMgmt_AutoPReq_Flg
    connect CtAp_AutoSftGear.RTE_P_GearMgmt_NotP2PReq_Flg -> CtAp_EPBLink.RTE_R_GearMgmt_NotP2PReq_Flg
    connect CtAp_AutoSftGear.RTE_P_GearMgmt_AutoNReq_Flg -> CtAp_GearCoor.RTE_R_GearMgmt_AutoNReq_Flg
    connect CtAp_AutoSftGear.RTE_P_GearMgmt_P2NReq_Flg -> CtAp_GearCoor.RTE_R_GearMgmt_P2NReq_Flg
    connect CtAp_AutoSftGear.RTE_P_GearMgmt_AutoPReq_Flg -> CtAp_GearDiag.RTE_R_GearMgmt_AutoPReq_Flg
    connect CtAp_EPBLink.RTE_P_GearMgmt_AllowGearShift2P_Flg -> CtAp_GearCoor.RTE_R_GearMgmt_AllowGearShift2P_Flg
    connect CtAp_EPBLink.RTE_P_GearMgmt_EPBPrkReqFail_Flg -> CtAp_GearDiag.RTE_R_GearMgmt_EPBPrkReqFail_Flg
    connect CtAp_EPBLink.RTE_P_GearMgmt_EPBPrkType_Enum -> CtAp_GearDiag.RTE_R_GearMgmt_EPBPrkType_Enum
    connect CtAp_EPBLink.RTE_P_GearMgmt_EPBRelsReqFail_Flg -> CtAp_GearDiag.RTE_R_GearMgmt_EPBRelsReqFail_Flg
    connect CtAp_EPBLink.RTE_P_GearMgmt_EPBPrkReqCmpl_Flg -> CtAp_ManSftGear.RTE_R_GearMgmt_EPBPrkReqCmpl_Flg
    connect CtAp_EPBLink.RTE_P_GearMgmt_EPBRelsReqCmpl_Flg -> CtAp_ManSftGear.RTE_R_GearMgmt_EPBRelsReqCmpl_Flg
    connect CtAp_GearCoor.RTE_P_GearMgmt_ActGear_Enum -> CtAp_AutoSftGear.RTE_R_GearMgmt_ActGear_Enum
    connect CtAp_GearCoor.RTE_P_GearMgmt_WakeUpEPBReq_Flg -> CtAp_EPBLink.RTE_R_GearMgmt_WakeUpEPBReq_Flg
    connect CtAp_GearCoor.RTE_P_GearMgmt_ActGear_Enum -> CtAp_ManSftGear.RTE_R_GearMgmt_ActGear_Enum
    connect CtAp_GearCoor.RTE_P_GearMgmt_WakeUpFinish_Flg -> CtAp_ManSftGear.RTE_R_GearMgmt_WakeUpFinish_Flg
    connect CtAp_ManSftGear.RTE_P_GearMgmt_InPlugDetd_Flg -> CtAp_AutoSftGear.RTE_R_GearMgmt_InPlugDetd_Flg
    connect CtAp_ManSftGear.RTE_P_GearMgmt_AllowGearShiftWait_Enum -> CtAp_EPBLink.RTE_R_GearMgmt_AllowGearShiftWait_Enum
    connect CtAp_ManSftGear.RTE_P_GearMgmt_AllowGearShift_Enum -> CtAp_GearCoor.RTE_R_GearMgmt_AllowGearShift_Enum
    connect CtAp_ManSftGear.RTE_P_GearMgmt_InPlugDetd_Flg -> CtAp_GearDiag.RTE_R_GearMgmt_InPlugDetd_Flg
    connect CtAp_ManSftGear.RTE_P_GearMgmt_TarGearShift_Enum -> CtAp_GearDiag.RTE_R_GearMgmt_TarGearShift_Enum
    delegate CtAp_GearCoor.RTE_P_GearMgmt_ActGear_Enum <-> outer port CtAp_GearMgmt/RTE_P_GearMgmt_ActGear_Enum
    delegate CtAp_ManSftGear.RTE_P_GearMgmt_AllowGearShift_Enum <-> outer port CtAp_GearMgmt/RTE_P_GearMgmt_AllowGearShift_Enum
    delegate CtAp_EPBLink.RTE_P_GearMgmt_AllowGearShift2P_Flg <-> outer port CtAp_GearMgmt/RTE_P_GearMgmt_AllowGearShift2P_Flg
    delegate CtAp_ManSftGear.RTE_P_GearMgmt_AllowGearShiftWait_Enum <-> outer port CtAp_GearMgmt/RTE_P_GearMgmt_AllowGearShiftWait_Enum
    delegate CtAp_AutoSftGear.RTE_P_GearMgmt_AutoNReq_Flg <-> outer port CtAp_GearMgmt/RTE_P_GearMgmt_AutoNReq_Flg
    delegate CtAp_AutoSftGear.RTE_P_GearMgmt_AutoPNSts_Flg <-> outer port CtAp_GearMgmt/RTE_P_GearMgmt_AutoPNSts_Flg
    delegate CtAp_AutoSftGear.RTE_P_GearMgmt_AutoPReq_Flg <-> outer port CtAp_GearMgmt/RTE_P_GearMgmt_AutoPReq_Flg
    delegate CtAp_EPBLink.RTE_P_GearMgmt_EPBPrkReq_Flg <-> outer port CtAp_GearMgmt/RTE_P_GearMgmt_EPBPrkReq_Flg
    delegate CtAp_EPBLink.RTE_P_GearMgmt_EPBPrkReqCmpl_Flg <-> outer port CtAp_GearMgmt/RTE_P_GearMgmt_EPBPrkReqCmpl_Flg
    delegate CtAp_EPBLink.RTE_P_GearMgmt_EPBPrkReqFail_Flg <-> outer port CtAp_GearMgmt/RTE_P_GearMgmt_EPBPrkReqFail_Flg
    delegate CtAp_EPBLink.RTE_P_GearMgmt_EPBPrkType_Enum <-> outer port CtAp_GearMgmt/RTE_P_GearMgmt_EPBPrkType_Enum
    delegate CtAp_EPBLink.RTE_P_GearMgmt_EPBRelsReq_Flg <-> outer port CtAp_GearMgmt/RTE_P_GearMgmt_EPBRelsReq_Flg
    delegate CtAp_EPBLink.RTE_P_GearMgmt_EPBRelsReqCmpl_Flg <-> outer port CtAp_GearMgmt/RTE_P_GearMgmt_EPBRelsReqCmpl_Flg
    delegate CtAp_EPBLink.RTE_P_GearMgmt_EPBRelsReqFail_Flg <-> outer port CtAp_GearMgmt/RTE_P_GearMgmt_EPBRelsReqFail_Flg
    delegate CtAp_ManSftGear.RTE_P_GearMgmt_InPlugDetd_Flg <-> outer port CtAp_GearMgmt/RTE_P_GearMgmt_InPlugDetd_Flg
    delegate CtAp_GearDiag.RTE_P_GearMgmt_InvldGearSel_Enum <-> outer port CtAp_GearMgmt/RTE_P_GearMgmt_InvldGearSel_Enum
    delegate CtAp_AutoSftGear.RTE_P_GearMgmt_NotP2PReq_Flg <-> outer port CtAp_GearMgmt/RTE_P_GearMgmt_NotP2PReq_Flg
    delegate CtAp_AutoSftGear.RTE_P_GearMgmt_P2NReq_Flg <-> outer port CtAp_GearMgmt/RTE_P_GearMgmt_P2NReq_Flg
    delegate CtAp_ManSftGear.RTE_P_GearMgmt_TarGear_Enum <-> outer port CtAp_GearMgmt/RTE_P_GearMgmt_TarGear_Enum
    delegate CtAp_GearCoor.RTE_P_GearMgmt_TarGearPInhbTq_Flg <-> outer port CtAp_GearMgmt/RTE_P_GearMgmt_TarGearPInhbTq_Flg
    delegate CtAp_ManSftGear.RTE_P_GearMgmt_TarGearShift_Enum <-> outer port CtAp_GearMgmt/RTE_P_GearMgmt_TarGearShift_Enum
    delegate CtAp_GearCoor.RTE_P_GearMgmt_WakeUpEPBReq_Flg <-> outer port CtAp_GearMgmt/RTE_P_GearMgmt_WakeUpEPBReq_Flg
    delegate CtAp_GearCoor.RTE_P_GearMgmt_WakeUpFinish_Flg <-> outer port CtAp_GearMgmt/RTE_P_GearMgmt_WakeUpFinish_Flg
    delegate CtAp_GearDiag.RTE_R_ChassisMgmt_AccrPedlPosn_pct <-> outer port CtAp_GearMgmt/RTE_R_ChassisMgmt_AccrPedlPosn_pct
    delegate CtAp_ManSftGear.RTE_R_ChassisMgmt_AccrPedlPosn_pct <-> outer port CtAp_GearMgmt/RTE_R_ChassisMgmt_AccrPedlPosn_pct
    delegate CtAp_GearDiag.RTE_R_ChassisMgmt_AccrPedlVld_Flg <-> outer port CtAp_GearMgmt/RTE_R_ChassisMgmt_AccrPedlVld_Flg
    delegate CtAp_ManSftGear.RTE_R_ChassisMgmt_AccrPedlVld_Flg <-> outer port CtAp_GearMgmt/RTE_R_ChassisMgmt_AccrPedlVld_Flg
    delegate CtAp_GearDiag.RTE_R_ChassisMgmt_BrkSts_Flg <-> outer port CtAp_GearMgmt/RTE_R_ChassisMgmt_BrkSts_Flg
    delegate CtAp_ManSftGear.RTE_R_ChassisMgmt_BrkSts_Flg <-> outer port CtAp_GearMgmt/RTE_R_ChassisMgmt_BrkSts_Flg
    delegate CtAp_GearDiag.RTE_R_ChassisMgmt_BrkStsVld_Flg <-> outer port CtAp_GearMgmt/RTE_R_ChassisMgmt_BrkStsVld_Flg
    delegate CtAp_ManSftGear.RTE_R_ChassisMgmt_BrkStsVld_Flg <-> outer port CtAp_GearMgmt/RTE_R_ChassisMgmt_BrkStsVld_Flg
    delegate CtAp_ManSftGear.RTE_R_ChrMgmt_ChrgSts_Enum <-> outer port CtAp_GearMgmt/RTE_R_ChrMgmt_ChrgSts_Enum
    delegate CtAp_AutoSftGear.RTE_R_ComM_ACUDrvSeatBltSts_Flg <-> outer port CtAp_GearMgmt/RTE_R_ComM_ACUDrvSeatBltSts_Flg
    delegate CtAp_AutoSftGear.RTE_R_ComM_ACUDrvSeatBltStsVld_Flg <-> outer port CtAp_GearMgmt/RTE_R_ComM_ACUDrvSeatBltStsVld_Flg
    delegate CtAp_AutoSftGear.RTE_R_ComM_ADCUDMSDrvExist_Flg <-> outer port CtAp_GearMgmt/RTE_R_ComM_ADCUDMSDrvExist_Flg
    delegate CtAp_AutoSftGear.RTE_R_ComM_DCMFLDoorSts_Flg <-> outer port CtAp_GearMgmt/RTE_R_ComM_DCMFLDoorSts_Flg
    delegate CtAp_AutoSftGear.RTE_R_ComM_EPBWrkSts_Enum <-> outer port CtAp_GearMgmt/RTE_R_ComM_EPBWrkSts_Enum
    delegate CtAp_EPBLink.RTE_R_ComM_EPBWrkSts_Enum <-> outer port CtAp_GearMgmt/RTE_R_ComM_EPBWrkSts_Enum
    delegate CtAp_GearCoor.RTE_R_ComM_EPBWrkSts_Enum <-> outer port CtAp_GearMgmt/RTE_R_ComM_EPBWrkSts_Enum
    delegate CtAp_GearDiag.RTE_R_ComM_EPBWrkSts_Enum <-> outer port CtAp_GearMgmt/RTE_R_ComM_EPBWrkSts_Enum
    delegate CtAp_ManSftGear.RTE_R_ComM_EPBWrkSts_Enum <-> outer port CtAp_GearMgmt/RTE_R_ComM_EPBWrkSts_Enum
    delegate CtAp_ManSftGear.RTE_R_ComM_GearPBtn_Enum <-> outer port CtAp_GearMgmt/RTE_R_ComM_GearPBtn_Enum
    delegate CtAp_GearDiag.RTE_R_ComM_GearPBtnFltSts_Flg <-> outer port CtAp_GearMgmt/RTE_R_ComM_GearPBtnFltSts_Flg
    delegate CtAp_ManSftGear.RTE_R_ComM_GearPBtnFltSts_Flg <-> outer port CtAp_GearMgmt/RTE_R_ComM_GearPBtnFltSts_Flg
    delegate CtAp_ManSftGear.RTE_R_ComM_GearRNDBtn_Enum <-> outer port CtAp_GearMgmt/RTE_R_ComM_GearRNDBtn_Enum
    delegate CtAp_GearDiag.RTE_R_ComM_GearRNDBtnFltSts_Flg <-> outer port CtAp_GearMgmt/RTE_R_ComM_GearRNDBtnFltSts_Flg
    delegate CtAp_ManSftGear.RTE_R_ComM_GearRNDBtnFltSts_Flg <-> outer port CtAp_GearMgmt/RTE_R_ComM_GearRNDBtnFltSts_Flg
    delegate CtAp_ManSftGear.RTE_R_ComM_IBSTarGearReq_Enum <-> outer port CtAp_GearMgmt/RTE_R_ComM_IBSTarGearReq_Enum
    delegate CtAp_ManSftGear.RTE_R_ComM_IVIGearReq_Enum <-> outer port CtAp_GearMgmt/RTE_R_ComM_IVIGearReq_Enum
    delegate CtAp_AutoSftGear.RTE_R_ComM_PEPSPwrMod_Enum <-> outer port CtAp_GearMgmt/RTE_R_ComM_PEPSPwrMod_Enum
    delegate CtAp_AutoSftGear.RTE_R_ModMgmt_HvSts_Enum <-> outer port CtAp_GearMgmt/RTE_R_ModMgmt_HvSts_Enum
    delegate CtAp_GearDiag.RTE_R_ModMgmt_HvSts_Enum <-> outer port CtAp_GearMgmt/RTE_R_ModMgmt_HvSts_Enum
    delegate CtAp_ManSftGear.RTE_R_ModMgmt_HvSts_Enum <-> outer port CtAp_GearMgmt/RTE_R_ModMgmt_HvSts_Enum
    delegate CtAp_AutoSftGear.RTE_R_VehMot_VehSpd_kph <-> outer port CtAp_GearMgmt/RTE_R_VehMot_VehSpd_kph
    delegate CtAp_GearCoor.RTE_R_VehMot_VehSpd_kph <-> outer port CtAp_GearMgmt/RTE_R_VehMot_VehSpd_kph
    delegate CtAp_GearDiag.RTE_R_VehMot_VehSpd_kph <-> outer port CtAp_GearMgmt/RTE_R_VehMot_VehSpd_kph
    delegate CtAp_ManSftGear.RTE_R_VehMot_VehSpd_kph <-> outer port CtAp_GearMgmt/RTE_R_VehMot_VehSpd_kph
  5 x swc implementation:
    CtAp_AutoSftGear_Implementation: behavior=CtAp_AutoSftGear_InternalBehavior
      code-descriptors:
        code Default: artifact-descriptors=autosar-engineering-object={short-label=Default, category=SWOBJ}
    CtAp_EPBLink_Implementation: behavior=CtAp_EPBLink_InternalBehavior
      code-descriptors:
        code Default: artifact-descriptors=autosar-engineering-object={short-label=Default, category=SWOBJ}
    CtAp_GearCoor_Implementation: behavior=CtAp_GearCoor_InternalBehavior
      code-descriptors:
        code Default: artifact-descriptors=autosar-engineering-object={short-label=Default, category=SWOBJ}
    CtAp_GearDiag_Implementation: behavior=CtAp_GearDiag_InternalBehavior
      code-descriptors:
        code Default: artifact-descriptors=autosar-engineering-object={short-label=Default, category=SWOBJ}
    CtAp_ManSftGear_Implementation: behavior=CtAp_ManSftGear_InternalBehavior
      code-descriptors:
        code Default: artifact-descriptors=autosar-engineering-object={short-label=Default, category=SWOBJ}
package /PortInterfaces
  42 x sender receiver interface:
    IF_ChassisMgmt_AccrPedlPosn_pct: invalidation-policy{data-element=tec_ChassisMgmt_AccrPedlPosn_pct, handle-invalid=DONT-INVALIDATE}
      data tec_ChassisMgmt_AccrPedlPosn_pct: type=float32
    IF_ChassisMgmt_AccrPedlVld_Flg: invalidation-policy{data-element=tec_ChassisMgmt_AccrPedlVld_Flg, handle-invalid=DONT-INVALIDATE}
      data tec_ChassisMgmt_AccrPedlVld_Flg: type=boolean
    IF_ChassisMgmt_BrkSts_Flg: invalidation-policy{data-element=tec_ChassisMgmt_BrkSts_Flg, handle-invalid=DONT-INVALIDATE}
      data tec_ChassisMgmt_BrkSts_Flg: type=boolean
    IF_ChassisMgmt_BrkStsVld_Flg: invalidation-policy{data-element=tec_ChassisMgmt_BrkStsVld_Flg, handle-invalid=DONT-INVALIDATE}
      data tec_ChassisMgmt_BrkStsVld_Flg: type=boolean
    IF_ChrMgmt_ChrgSts_Enum: invalidation-policy{data-element=tec_ChrMgmt_ChrgSts_Enum, handle-invalid=DONT-INVALIDATE}
      data tec_ChrMgmt_ChrgSts_Enum: type=uint8
    IF_ComM_ACUDrvSeatBltSts_Flg: invalidation-policy{data-element=tec_ComM_ACUDrvSeatBltSts_Flg, handle-invalid=DONT-INVALIDATE}
      data tec_ComM_ACUDrvSeatBltSts_Flg: type=boolean
    IF_ComM_ACUDrvSeatBltStsVld_Flg: invalidation-policy{data-element=tec_ComM_ACUDrvSeatBltStsVld_Flg, handle-invalid=DONT-INVALIDATE}
      data tec_ComM_ACUDrvSeatBltStsVld_Flg: type=boolean
    IF_ComM_ADCUDMSDrvExist_Flg: invalidation-policy{data-element=tec_ComM_ADCUDMSDrvrExist_Flg, handle-invalid=DONT-INVALIDATE}
      data tec_ComM_ADCUDMSDrvrExist_Flg: type=boolean
    IF_ComM_DCMFLDoorSts_Flg: invalidation-policy{data-element=tec_ComM_DCMFLDoorSts_Flg, handle-invalid=DONT-INVALIDATE}
      data tec_ComM_DCMFLDoorSts_Flg: type=boolean
    IF_ComM_EPBWrkSts_Enum: invalidation-policy{data-element=tec_ComM_EPBWrkSts_Enum, handle-invalid=DONT-INVALIDATE}
      data tec_ComM_EPBWrkSts_Enum: type=uint8
    IF_ComM_GearPBtn_Enum: invalidation-policy{data-element=tec_ComM_GearPBtn_Enum, handle-invalid=DONT-INVALIDATE}
      data tec_ComM_GearPBtn_Enum: type=uint8
    IF_ComM_GearPBtnFltSts_Flg: invalidation-policy{data-element=tec_ComM_GearPBtnFltSts_Flg, handle-invalid=DONT-INVALIDATE}
      data tec_ComM_GearPBtnFltSts_Flg: type=boolean
    IF_ComM_GearRNDBtn_Enum: invalidation-policy{data-element=tec_ComM_GearRNDBtn_Enum, handle-invalid=DONT-INVALIDATE}
      data tec_ComM_GearRNDBtn_Enum: type=uint8
    IF_ComM_GearRNDBtnFltSts_Flg: invalidation-policy{data-element=tec_ComM_GearRNDBtnFltSts_Flg, handle-invalid=DONT-INVALIDATE}
      data tec_ComM_GearRNDBtnFltSts_Flg: type=boolean
    IF_ComM_IBSTarGearReq_Enum: invalidation-policy{data-element=tec_ComM_IBSTarGearReq_Enum, handle-invalid=DONT-INVALIDATE}
      data tec_ComM_IBSTarGearReq_Enum: type=uint8
    IF_ComM_IVIGearReq_Enum: invalidation-policy{data-element=tec_ComM_IVIGearReq_Enum, handle-invalid=DONT-INVALIDATE}
      data tec_ComM_IVIGearReq_Enum: type=uint8
    IF_ComM_PEPSPwrMod_Enum: invalidation-policy{data-element=tec_ComM_PEPSPwrMod_Enum, handle-invalid=DONT-INVALIDATE}
      data tec_ComM_PEPSPwrMod_Enum: type=uint8
    IF_GearMgmt_ActGear_Enum: invalidation-policy{data-element=tec_GearMgmt_ActGear_Enum, handle-invalid=DONT-INVALIDATE}
      data tec_GearMgmt_ActGear_Enum: type=uint8
    IF_GearMgmt_AllowGearShift_Enum: invalidation-policy{data-element=tec_GearMgmt_AllowGearShift_Enum, handle-invalid=DONT-INVALIDATE}
      data tec_GearMgmt_AllowGearShift_Enum: type=uint8
    IF_GearMgmt_AllowGearShift2P_Flg: invalidation-policy{data-element=tec_GearMgmt_AllowGearShift2P_Flg, handle-invalid=DONT-INVALIDATE}
      data tec_GearMgmt_AllowGearShift2P_Flg: type=boolean
    IF_GearMgmt_AllowGearShiftWait_Enum: invalidation-policy{data-element=tec_GearMgmt_AllowGearShiftWait_Enum, handle-invalid=DONT-INVALIDATE}
      data tec_GearMgmt_AllowGearShiftWait_Enum: type=uint8
    IF_GearMgmt_AutoNReq_Flg: invalidation-policy{data-element=tec_GearMgmt_AutoNReq_Flg, handle-invalid=DONT-INVALIDATE}
      data tec_GearMgmt_AutoNReq_Flg: type=boolean
    IF_GearMgmt_AutoPNSts_Flg: invalidation-policy{data-element=tec_GearMgmt_AutoPNSts_Flg, handle-invalid=DONT-INVALIDATE}
      data tec_GearMgmt_AutoPNSts_Flg: type=boolean
    IF_GearMgmt_AutoPReq_Flg: invalidation-policy{data-element=tec_GearMgmt_AutoPReq_Flg, handle-invalid=DONT-INVALIDATE}
      data tec_GearMgmt_AutoPReq_Flg: type=boolean
    IF_GearMgmt_EPBPrkReq_Flg: invalidation-policy{data-element=tec_GearMgmt_EPBPrkReq_Flg, handle-invalid=DONT-INVALIDATE}
      data tec_GearMgmt_EPBPrkReq_Flg: type=boolean
    IF_GearMgmt_EPBPrkReqCmpl_Flg: invalidation-policy{data-element=tec_GearMgmt_EPBPrkReqCmpl_Flg, handle-invalid=DONT-INVALIDATE}
      data tec_GearMgmt_EPBPrkReqCmpl_Flg: type=boolean
    IF_GearMgmt_EPBPrkReqFail_Flg: invalidation-policy{data-element=tec_GearMgmt_EPBPrkReqFail_Flg, handle-invalid=DONT-INVALIDATE}
      data tec_GearMgmt_EPBPrkReqFail_Flg: type=boolean
    IF_GearMgmt_EPBPrkType_Enum: invalidation-policy{data-element=tec_GearMgmt_EPBPrkType_Enum, handle-invalid=DONT-INVALIDATE}
      data tec_GearMgmt_EPBPrkType_Enum: type=uint8
    IF_GearMgmt_EPBRelsReq_Flg: invalidation-policy{data-element=tec_GearMgmt_EPBRelsReq_Flg, handle-invalid=DONT-INVALIDATE}
      data tec_GearMgmt_EPBRelsReq_Flg: type=boolean
    IF_GearMgmt_EPBRelsReqCmpl_Flg: invalidation-policy{data-element=tec_GearMgmt_EPBRelsReqCmpl_Flg, handle-invalid=DONT-INVALIDATE}
      data tec_GearMgmt_EPBRelsReqCmpl_Flg: type=boolean
    IF_GearMgmt_EPBRelsReqFail_Flg: invalidation-policy{data-element=tec_GearMgmt_EPBRelsReqFail_Flg, handle-invalid=DONT-INVALIDATE}
      data tec_GearMgmt_EPBRelsReqFail_Flg: type=boolean
    IF_GearMgmt_InPlugDetd_Flg: invalidation-policy{data-element=tec_GearMgmt_InPlugDetd_Flg, handle-invalid=DONT-INVALIDATE}
      data tec_GearMgmt_InPlugDetd_Flg: type=boolean
    IF_GearMgmt_InvldGearSel_Enum: invalidation-policy{data-element=tec_GearMgmt_InvldGearSel_Enum, handle-invalid=DONT-INVALIDATE}
      data tec_GearMgmt_InvldGearSel_Enum: type=uint8
    IF_GearMgmt_NotP2PReq_Flg: invalidation-policy{data-element=tec_GearMgmt_NotP2PReq_Flg, handle-invalid=DONT-INVALIDATE}
      data tec_GearMgmt_NotP2PReq_Flg: type=boolean
    IF_GearMgmt_P2NReq_Flg: invalidation-policy{data-element=tec_GearMgmt_P2NReq_Flg, handle-invalid=DONT-INVALIDATE}
      data tec_GearMgmt_P2NReq_Flg: type=boolean
    IF_GearMgmt_TarGear_Enum: invalidation-policy{data-element=tec_GearMgmt_TarGear_Enum, handle-invalid=DONT-INVALIDATE}
      data tec_GearMgmt_TarGear_Enum: type=uint8
    IF_GearMgmt_TarGearPInhbTq_Flg: invalidation-policy{data-element=tec_GearMgmt_TarGearPInhbTq_Flg, handle-invalid=DONT-INVALIDATE}
      data tec_GearMgmt_TarGearPInhbTq_Flg: type=boolean
    IF_GearMgmt_TarGearShift_Enum: invalidation-policy{data-element=tec_GearMgmt_TarGearShift_Enum, handle-invalid=DONT-INVALIDATE}
      data tec_GearMgmt_TarGearShift_Enum: type=uint8
    IF_GearMgmt_WakeUpEPBReq_Flg: invalidation-policy{data-element=tec_GearMgmt_WakeUpEPBReq_Flg, handle-invalid=DONT-INVALIDATE}
      data tec_GearMgmt_WakeUpEPBReq_Flg: type=boolean
    IF_GearMgmt_WakeUpFinish_Flg: invalidation-policy{data-element=tec_GearMgmt_WakeUpFinish_Flg, handle-invalid=DONT-INVALIDATE}
      data tec_GearMgmt_WakeUpFinish_Flg: type=boolean
    IF_ModMgmt_HvSts_Enum: invalidation-policy{data-element=tec_ModMgmt_HvSts_Enum, handle-invalid=DONT-INVALIDATE}
      data tec_ModMgmt_HvSts_Enum: type=uint8
    IF_VehMot_VehSpd_kph: invalidation-policy{data-element=tec_VehMot_VehSpd_kph, handle-invalid=DONT-INVALIDATE}
      data tec_VehMot_VehSpd_kph: type=float32
